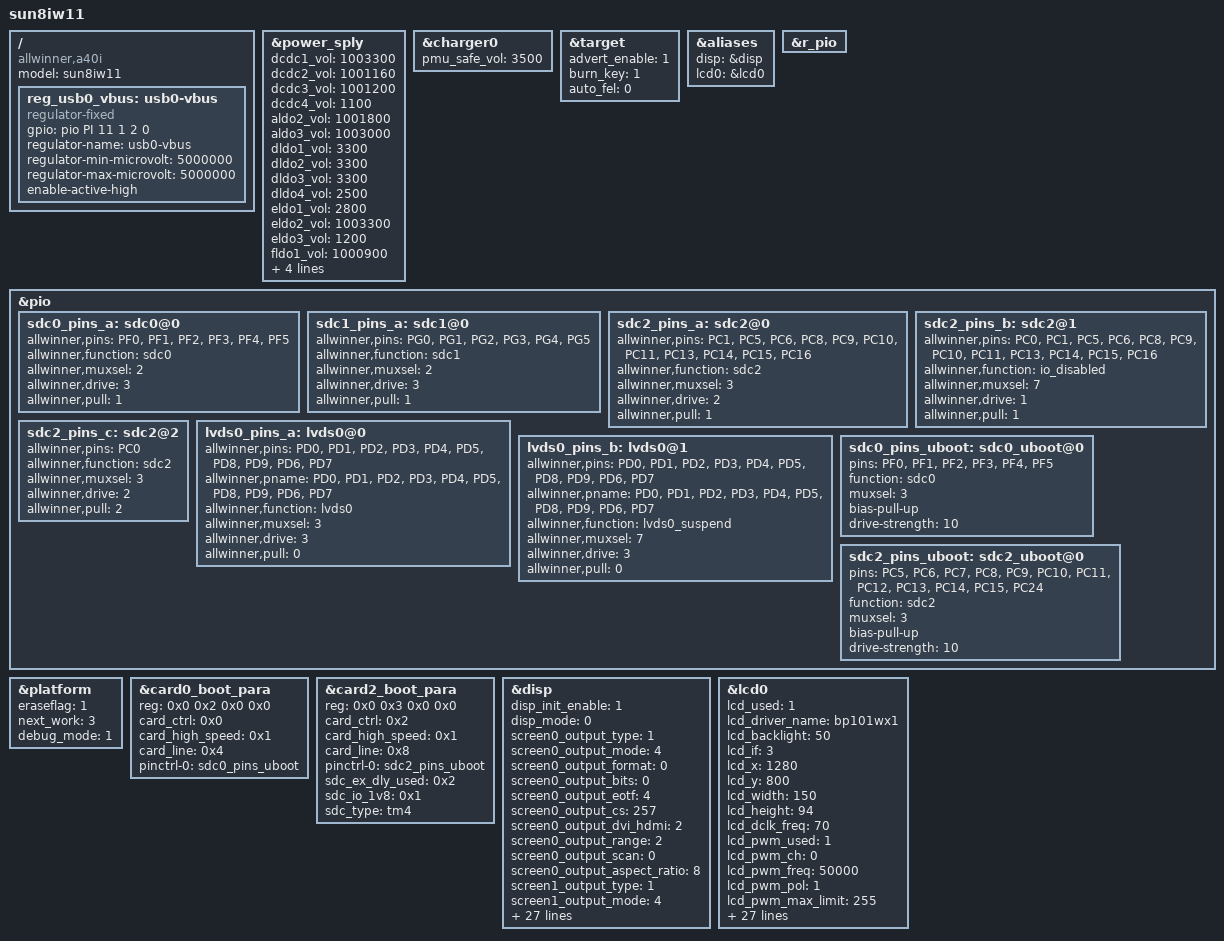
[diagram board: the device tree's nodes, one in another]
/*
 * Allwinner Technology CO., Ltd. sun8iw19p1 soc board.
 *
 * soc board support.
 */

/{
	model = "sun8iw11";
	compatible = "allwinner,a40i", "arm,sun8w11p1";

	reg_usb0_vbus: usb0-vbus {
		compatible = "regulator-fixed";
		gpio = <&pio PI 11 1 2 0 1>;
		regulator-name = "usb0-vbus";
		regulator-min-microvolt = <5000000>;
		regulator-max-microvolt = <5000000>;
		enable-active-high;
	};
};

&power_sply {
	dcdc1_vol = <1003300>;
	dcdc2_vol = <1001160>;
	dcdc3_vol = <1001200>;
	dcdc4_vol = <1100>;
	aldo2_vol = <0003300>;
	aldo2_vol = <1001800>;
	aldo3_vol = <1003000>;
	dldo1_vol = <3300>;
	dldo2_vol = <3300>;
	dldo3_vol = <3300>;
	dldo4_vol = <2500>;
	eldo1_vol = <2800>;
	eldo2_vol = <1003300>;
	eldo3_vol = <1200>;
	fldo1_vol = <1000900>;
	dc1sw_vol = <3000>;
	dc5ldo_vol = <1100>;
	ldo_io0_vol = <1003300>;
	ldo_io1_vol = <1003300>;
};

&charger0 {
	pmu_safe_vol = <3500>;
};

&target {
	advert_enable = <1>;
	burn_key = <1>;
	auto_fel = <0>;
};

&aliases {
	disp = &disp;
	lcd0 = &lcd0;
};

&r_pio{
};


&pio{
	sdc0_pins_a: sdc0@0 {
		allwinner,pins = "PF0", "PF1", "PF2",
				 "PF3", "PF4", "PF5";
		allwinner,function = "sdc0";
		allwinner,muxsel = <2>;
		allwinner,drive = <3>;
		allwinner,pull = <1>;
	};
	sdc1_pins_a: sdc1@0 {
		allwinner,pins = "PG0", "PG1", "PG2",
				 "PG3", "PG4", "PG5";
		allwinner,function = "sdc1";
		allwinner,muxsel = <2>;
		allwinner,drive = <3>;
		allwinner,pull = <1>;
	};
	sdc2_pins_a: sdc2@0 {
		allwinner,pins = "PC1", "PC5", "PC6",
				 "PC8", "PC9", "PC10", "PC11",
				 "PC13", "PC14", "PC15", "PC16";
		allwinner,function = "sdc2";
		allwinner,muxsel = <3>;
		allwinner,drive = <2>;
		allwinner,pull = <1>;
	};
	sdc2_pins_b: sdc2@1 {
		allwinner,pins = "PC0", "PC1", "PC5", "PC6",
				 "PC8", "PC9", "PC10", "PC11",
				 "PC13", "PC14", "PC15", "PC16";
		allwinner,function = "io_disabled";
		allwinner,muxsel = <7>;
		allwinner,drive = <1>;
		allwinner,pull = <1>;
	};
	sdc2_pins_c: sdc2@2 {
		allwinner,pins = "PC0";
		allwinner,function = "sdc2";
		allwinner,muxsel = <3>;
		allwinner,drive = <2>;
		allwinner,pull = <2>;
	};
};

&platform {
	eraseflag   = <1>;
	next_work   = <3>;
	debug_mode  = <1>;
};

&card0_boot_para {
	/* Avoid dtc compiling warnings. */
	reg = <0x0 0x2 0x0 0x0>;
	device_type = "card0_boot_para";
	card_ctrl = <0x0>;
	card_high_speed = <0x1>;
	card_line = <0x4>;
	pinctrl-0 = <&sdc0_pins_uboot>;
};

&card2_boot_para {
	/* Avoid dtc compiling warnings. */
	reg = <0x0 0x3 0x0 0x0>;
	device_type = "card2_boot_para";
	card_ctrl = <0x2>;
	card_high_speed = <0x1>;
	card_line = <0x8>;
	pinctrl-0 = <&sdc2_pins_uboot>;
	sdc_ex_dly_used = <0x2>;
	sdc_io_1v8 = <0x1>;
	sdc_type = "tm4";
};

&disp {
	disp_init_enable         = <1>;
	disp_mode                = <0>;

	screen0_output_type      = <1>;
	screen0_output_mode      = <4>;
	screen0_output_format    = <0>;
	screen0_output_bits      = <0>;
	screen0_output_eotf      = <4>;
	screen0_output_cs        = <257>;
	screen0_output_dvi_hdmi  = <2>;
	screen0_output_range     = <2>;
	screen0_output_scan      = <0>;
	screen0_output_aspect_ratio = <8>;

	screen1_output_type      = <1>;
	screen1_output_mode      = <4>;
	screen1_output_format    = <0>;
	screen1_output_bits      = <0>;
	screen1_output_eotf      = <4>;
	screen1_output_cs        = <257>;
	screen1_output_dvi_hdmi  = <2>;
	screen1_output_range     = <2>;
	screen1_output_scan      = <0>;
	screen1_output_aspect_ratio = <8>;
	dev0_output_type         = <1>;
	dev0_output_mode         = <4>;
	dev0_screen_id           = <0>;
	dev0_do_hpd              = <0>;

	dev1_output_type         = <1>;
	dev1_output_mode         = <4>;
	dev1_screen_id           = <1>;
	dev1_do_hpd              = <1>;

	dev2_output_type         = <0>;
	def_output_dev           = <0>;
	hdmi_mode_check          = <1>;

	fb0_format               = <0>;
	fb0_width                = <1280>;
	fb0_height               = <800>;

	fb1_format               = <0>;
	fb1_width                = <0>;
	fb1_height               = <0>;

	chn_cfg_mode             = <1>;

	disp_para_zone           = <1>;
	// /* VCC-LVDS and VCC-HDMI */
	// bldo1-supply = <&reg_bldo1>;
	// /* VCC-TV */
	// cldo4-supply = <&reg_cldo4>;
};

// &hdmi {
// 	hdmi_used = <1>;
// 	bldo1-supply = <&reg_bldo1>;
// 	hdmi_power0 = "bldo1";
// 	hdmi_power_cnt = <1>;
// 	hdmi_hdcp_enable = <1>;
// 	hdmi_hdcp22_enable = <1>;
// 	hdmi_cts_compatibility = <0>;
// 	hdmi_cec_support = <1>;
// 	hdmi_cec_super_standby = <0>;
// 	hdmi_skip_bootedid = <1>;

// 	ddc_en_io_ctrl = <0>;
// 	power_io_ctrl = <0>;
// };

// &tv0 {
// 	interface       = <1>;
// 	dac_type0       = <0>;
// 	dac_src0        = <0>;
// 	tv_power        = "cldo4";

// 	status =  "okay";
// };

&lcd0{
	lcd_used            = <1>;

	lcd_driver_name     = "bp101wx1";
	lcd_backlight       = <50>;
	lcd_if              = <3>;

	lcd_x               = <1280>;
	lcd_y               = <800>;
	lcd_width           = <150>;
	lcd_height          = <94>;
	lcd_dclk_freq       = <70>;

	lcd_pwm_used        = <1>;
	lcd_pwm_ch          = <0>;
	lcd_pwm_freq        = <50000>;
	lcd_pwm_pol         = <1>;
	lcd_pwm_max_limit   = <255>;


	lcd_hbp             = <87>;
	lcd_ht              = <1450>;
	lcd_hspw            = <18>;
	lcd_vbp             = <23>;
	lcd_vt              = <860>;
	lcd_vspw            = <10>;

	lcd_lvds_if         = <0>;
	lcd_lvds_colordepth = <0>;
	lcd_lvds_mode       = <0>;
	lcd_frm             = <0>;
	lcd_hv_clk_phase    = <0>;
	lcd_hv_sync_polarity= <0>;
	lcd_gamma_en        = <0>;
	lcd_bright_curve_en = <0>;
	lcd_cmap_en         = <0>;
	lcd_fsync_en        = <0>;
	lcd_fsync_act_time  = <1000>;
	lcd_fsync_dis_time  = <1000>;
	lcd_fsync_pol       = <0>;

	deu_mode            = <0>;
	lcdgamma4iep        = <22>;
	smart_color         = <90>;

	lcd_pin_power = "bldo1";

	lcd_power = "dc1sw";
	lcd_bl_en        = <&pio PD 27 1 0 3 1>;
	pinctrl-0 = <&lvds0_pins_a>;
	pinctrl-1 = <&lvds0_pins_b>;
};

&pio{
	lvds0_pins_a: lvds0@0 {
		allwinner,pins = "PD0", "PD1", "PD2", "PD3", "PD4", "PD5", "PD8", "PD9", "PD6", "PD7";
		allwinner,pname = "PD0", "PD1", "PD2", "PD3", "PD4", "PD5", "PD8", "PD9", "PD6", "PD7";
		allwinner,function = "lvds0";
		allwinner,muxsel = <3>;
		allwinner,drive = <3>;
		allwinner,pull = <0>;
	};
	lvds0_pins_b: lvds0@1 {
		allwinner,pins = "PD0", "PD1", "PD2", "PD3", "PD4", "PD5", "PD8", "PD9", "PD6", "PD7";
		allwinner,pname = "PD0", "PD1", "PD2", "PD3", "PD4", "PD5", "PD8", "PD9", "PD6", "PD7";
		allwinner,function = "lvds0_suspend";
		allwinner,muxsel = <7>;
		allwinner,drive = <3>;
		allwinner,pull = <0>;
	};

	sdc0_pins_uboot: sdc0_uboot@0 {
		pins = "PF0", "PF1", "PF2", "PF3","PF4","PF5";
		function = "sdc0";
		muxsel = <3>;
		bias-pull-up;
		drive-strength = <10>;
	};

	sdc2_pins_uboot: sdc2_uboot@0 {
		pins = "PC5", "PC6","PC7", "PC8", "PC9","PC10","PC11","PC12","PC13","PC14","PC15","PC24";
		function = "sdc2";
		muxsel = <3>;
		bias-pull-up;
		drive-strength = <10>;
	};
};
